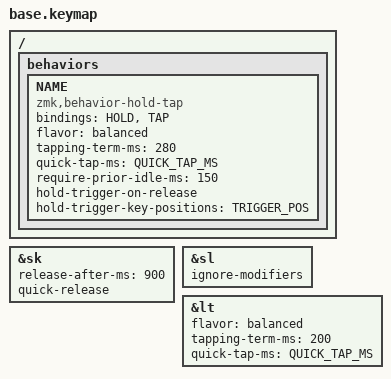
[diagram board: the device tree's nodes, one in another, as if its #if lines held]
#include <behaviors.dtsi>
#include <behaviors/num_word.dtsi> // Requires auto-layer module.
#include <dt-bindings/zmk/keys.h>
#ifdef CONFIG_WIRELESS
  #include <dt-bindings/zmk/bt.h>
  #include <dt-bindings/zmk/outputs.h>
  #define _BT_SEL_KEYS_                                                        \
      &bt BT_SEL 0 &bt BT_SEL 1 &bt BT_SEL 2 &bt BT_SEL 3 &bt BT_CLR
#else
  #define _BT_SEL_KEYS_ &trans &trans &trans &trans &trans
#endif

#include "zmk-helpers/helper.h"
#include "zmk-helpers/unicode-chars/greek.dtsi"
#include "zmk-helpers/unicode-chars/german.dtsi"

#define GLM 0
#define QWT 1
#define NAV 2
#define FN 3
#define NUM 4
#define SYS 5
#define MOUSE 6

#define XXX &none
#define ___ &trans

/* Global defaults */

#define QUICK_TAP_MS 175

&sk {
  release-after-ms = <900>;
  quick-release;
};

&sl { // Allow sticky mods to chord across sticky layers.
  ignore-modifiers;
};

&lt {
  flavor = "balanced";
  tapping-term-ms = <200>;
  quick-tap-ms = <QUICK_TAP_MS>;
};

/* Homerow mods */

#define KEYS_L LT0 LT1 LT2 LT3 LT4 LT5 LM0 LM1 LM2 LM3 LM4 LM5 LB0 LB1 LB2 LB3 LB4 LB5
#define KEYS_R RT0 RT1 RT2 RT3 RT4 RT5 RM0 RM1 RM2 RM3 RM4 RM5 RB0 RB1 RB2 RB3 RB4 RB5
#define THUMBS LH2 LH1 LH0 RH0 RH1 RH2


#define MAKE_HRM(NAME, HOLD, TAP, TRIGGER_POS)                                 \
  ZMK_HOLD_TAP(NAME, bindings = <HOLD>, <TAP>; flavor = "balanced";            \
               tapping-term-ms = <280>; quick-tap-ms = <QUICK_TAP_MS>;         \
               require-prior-idle-ms = <150>; hold-trigger-on-release;         \
               hold-trigger-key-positions = <TRIGGER_POS>;)

MAKE_HRM(hml, &kp, &kp, KEYS_R THUMBS) // Left-hand HRMs.
MAKE_HRM(hmr, &kp, &kp, KEYS_L THUMBS) // Right-hand HRMs.

// Hack: Make HRM combos tap-only (cf, ZMK issue #544).
#define ZMK_COMBO_8(NAME, TAP, POS, LAYERS, COMBO_MS, IDLE_MS, HOLD, SIDE)     \
  MAKE_HRM(hm_combo_##NAME, &kp, TAP, SIDE THUMBS)                             \
  ZMK_COMBO_6(NAME, &hm_combo_##NAME HOLD 0, POS, LAYERS, COMBO_MS, IDLE_MS)

/* Combos, leader key sequences, mouse emulation */
#include "definitions.dtsi"
#include "combos.dtsi" // Must be sourced after HRM-combo hack.
#include "leader.dtsi"
#include "mouse.dtsi"
#include "behaviors.dtsi"

/* Keymap */

ZMK_CONDITIONAL_LAYER(sys, FN NUM, SYS) // FN + NUM --> SYS.

#include "layers.dtsi"

/* vim: set ft=c tw=146: */
